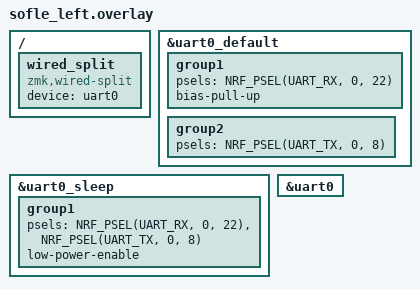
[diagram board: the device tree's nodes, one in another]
/*
 * Wired split over TRRS, full duplex (cable is straight-through):
 *   TRRS data ring  = D0 (P0.08), stock Sofle wiring
 *   TRRS spare ring = D4 (P0.22), jumper wire added on both halves
 * left half: TX on D0, RX on D4 (mirrored on the other half).
 */

&uart0_default {
    group1 {
        psels = <NRF_PSEL(UART_RX, 0, 22)>;
        bias-pull-up;
    };
    group2 {
        psels = <NRF_PSEL(UART_TX, 0, 8)>;  // replaces the board default D1, which drives the LEDs
    };
};

&uart0_sleep {
    group1 {
        psels = <NRF_PSEL(UART_RX, 0, 22)>,
                <NRF_PSEL(UART_TX, 0, 8)>;
        low-power-enable;
    };
};

&uart0 {
    status = "okay";
};

/ {
    wired_split {
        compatible = "zmk,wired-split";
        device = <&uart0>;
    };
};
